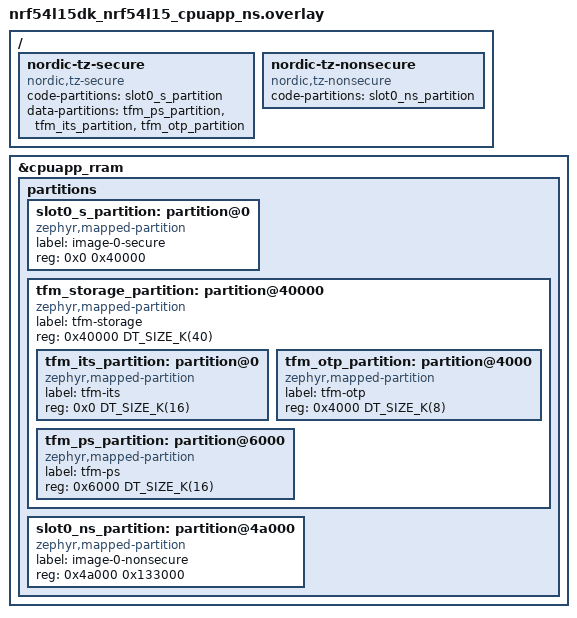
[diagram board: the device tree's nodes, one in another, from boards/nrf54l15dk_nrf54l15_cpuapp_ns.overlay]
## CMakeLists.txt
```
#
# Copyright (c) 2024 Nordic Semiconductor ASA
#
# SPDX-License-Identifier: LicenseRef-Nordic-5-Clause
#

cmake_minimum_required(VERSION 3.13.1)

find_package(Zephyr REQUIRED HINTS $ENV{ZEPHYR_BASE})
project(NONE)

FILE(GLOB app_sources src/*.c)
target_sources(app PRIVATE ${app_sources})
target_include_directories(app PRIVATE src)

add_subdirectory(tests)
```

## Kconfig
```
#
# Copyright (c) 2026 Nordic Semiconductor ASA
#
# SPDX-License-Identifier: LicenseRef-Nordic-5-Clause
#

configdefault HW_UNIQUE_KEY_WRITE_ON_CRYPTO_INIT
	default y

source "Kconfig.zephyr"
```

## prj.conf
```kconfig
#
# Copyright (c) 2021-2024 Nordic Semiconductor ASA
#
# SPDX-License-Identifier: LicenseRef-Nordic-5-Clause
#

CONFIG_ZTEST=y
CONFIG_ZTEST_STACK_SIZE=15360

CONFIG_SYS_CLOCK_TICKS_PER_SEC=1000
CONFIG_MAIN_STACK_SIZE=8192
CONFIG_HEAP_MEM_POOL_SIZE=8192

# Enable logging
CONFIG_CONSOLE=y

# Enable PSA Crypto API
CONFIG_PSA_CRYPTO=y
CONFIG_PSA_CRYPTO_DRIVER_CRACEN=y

CONFIG_HW_UNIQUE_KEY=y
# Ineffective here: unsatisfied dependency (!BUILD_WITH_TFM) on the _ns targets, so
# HW_UNIQUE_KEY_WRITE_ON_CRYPTO_INIT stays n there; moved to Kconfig as a default.
# CONFIG_HW_UNIQUE_KEY_WRITE_ON_CRYPTO_INIT=y

CONFIG_MBEDTLS_ENABLE_HEAP=y
CONFIG_MBEDTLS_HEAP_SIZE=8192

# Enable cryptographic features
CONFIG_PSA_WANT_ECC_TWISTED_EDWARDS_255=y
CONFIG_PSA_WANT_KEY_TYPE_ECC_KEY_PAIR_EXPORT=y

CONFIG_PSA_WANT_ALG_ECDSA=y
CONFIG_PSA_WANT_KEY_TYPE_ECC_KEY_PAIR_IMPORT=y
CONFIG_PSA_WANT_ECC_SECP_R1_256=y
CONFIG_PSA_WANT_ALG_SHA_256=y
CONFIG_PSA_WANT_ALG_SHA_512=y
CONFIG_PSA_WANT_KEY_TYPE_AES=y
CONFIG_PSA_WANT_ALG_CCM=y
CONFIG_PSA_WANT_ALG_CCM_STAR_NO_TAG=y
CONFIG_PSA_WANT_ALG_PURE_EDDSA=y

CONFIG_PSA_WANT_KEY_TYPE_ECC_KEY_PAIR_GENERATE=y
CONFIG_PSA_WANT_GENERATE_RANDOM=y
```

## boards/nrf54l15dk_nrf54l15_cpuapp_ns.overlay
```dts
/*
 * Copyright (c) 2026 Nordic Semiconductor ASA
 *
 * SPDX-License-Identifier: LicenseRef-Nordic-5-Clause
 */

/delete-node/ &slot0_partition;
/delete-node/ &slot0_ns_partition;
/delete-node/ &tfm_ps_partition;
/delete-node/ &tfm_its_partition;
/delete-node/ &tfm_otp_partition;
/delete-node/ &storage_partition;

&cpuapp_rram {
	partitions {
		slot0_s_partition: partition@0 {
			compatible = "zephyr,mapped-partition";
			label = "image-0-secure";
			reg = <0x0 0x40000>;
		};

		tfm_storage_partition: partition@40000 {
			compatible = "zephyr,mapped-partition";
			label = "tfm-storage";
			reg = <0x40000 DT_SIZE_K(40)>;
			ranges = <0x0 0x40000 DT_SIZE_K(40)>;
			#address-cells = <1>;
			#size-cells = <1>;

			tfm_its_partition: partition@0 {
				compatible = "zephyr,mapped-partition";
				label = "tfm-its";
				reg = <0x0 DT_SIZE_K(16)>;
			};

			tfm_otp_partition: partition@4000 {
				compatible = "zephyr,mapped-partition";
				label = "tfm-otp";
				reg = <0x4000 DT_SIZE_K(8)>;
			};

			tfm_ps_partition: partition@6000 {
				compatible = "zephyr,mapped-partition";
				label = "tfm-ps";
				reg = <0x6000 DT_SIZE_K(16)>;
			};
		};

		slot0_ns_partition: partition@4a000 {
			compatible = "zephyr,mapped-partition";
			label = "image-0-nonsecure";
			reg = <0x4a000 0x133000>;
		};
	};
};

/ {
	/delete-node/ nordic-tz-secure;
	/delete-node/ nordic-tz-nonsecure;

	nordic-tz-secure {
		compatible = "nordic,tz-secure";
		code-partitions = <&slot0_s_partition>;
		data-partitions = <&tfm_ps_partition>,
				  <&tfm_its_partition>,
				  <&tfm_otp_partition>;
	};

	nordic-tz-nonsecure {
		compatible = "nordic,tz-nonsecure";
		code-partitions = <&slot0_ns_partition>;
	};
};
```

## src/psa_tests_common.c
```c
/*
 * Copyright (c) 2024 Nordic Semiconductor ASA
 *
 * SPDX-License-Identifier: LicenseRef-Nordic-5-Clause
 */

#include <stdarg.h>
#include <string.h>
#include <stdint.h>
#include <stddef.h>
#include <zephyr/sys/printk.h>

#include <psa/crypto.h>
#include <psa/crypto_values.h>
#include <psa/crypto_extra.h>

#include <zephyr/sys/util.h>
#include <zephyr/sys/clock.h>
#include <zephyr/logging/log.h>
#include <zephyr/ztest.h>
#include "psa_tests_common.h"
#include <hw_unique_key.h>

#ifdef CONFIG_BUILD_WITH_TFM
#include <tfm_ns_interface.h>
#include <tfm_builtin_key_ids.h>
#include "cracen_psa_kmu.h"
#include <tfm_crypto_defs.h>
#else
#include <cracen_psa.h>
#endif

LOG_MODULE_REGISTER(ikg, LOG_LEVEL_INF);

ZTEST_SUITE(test_suite_ikg, NULL, NULL, NULL, NULL, NULL);

static psa_key_id_t key_id;

int crypto_init(void)
{
	psa_status_t status;

#if !defined(CONFIG_BUILD_WITH_TFM)
	if (!hw_unique_key_are_any_written()) {
		status = hw_unique_key_write_random();
		if (status != HW_UNIQUE_KEY_SUCCESS) {
			return status;
		}
	}
#endif
	status = psa_crypto_init();
	if (status != PSA_SUCCESS) {
		return status;
	}
	return APP_SUCCESS;
}

int crypto_finish(void)
{
	psa_status_t status;

	status = psa_destroy_key(key_id);
	if (status != PSA_SUCCESS) {
		return status;
	}

	return APP_SUCCESS;
}
```

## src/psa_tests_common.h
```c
/*
 * Copyright (c) 2024 Nordic Semiconductor ASA
 *
 * SPDX-License-Identifier: LicenseRef-Nordic-5-Clause
 */

#include <stdio.h>
#include <stdarg.h>
#include <stdint.h>
#include <zephyr/toolchain.h>
#include <zephyr/sys/util.h>
#include <zephyr/drivers/entropy.h>

#if defined(CONFIG_ZTEST)
#include <zephyr/ztest.h>
#endif

#define APP_SUCCESS		(0)
#define APP_ERROR		(-1)
#define APP_SUCCESS_MESSAGE "Example finished successfully!"
#define APP_ERROR_MESSAGE "Example exited with error!"

#ifndef TEST_MEMCMP
#define TEST_MEMCMP(x, y, size) ((memcmp(x, y, size) == 0) ? 0 : 1)
#endif

/**@brief Macro asserting equality.
 */
#ifndef TEST_VECTOR_ASSERT_EQUAL
#define TEST_VECTOR_ASSERT_EQUAL(expected, actual)                             \
	zassert_equal((expected), (actual),                                    \
			  "\tAssert values: 0x%04X != -0x%04X", (expected),        \
			  (-actual))
#endif

/**@brief Macro asserting inequality.
 */
#ifndef TEST_VECTOR_ASSERT_NOT_EQUAL
#define TEST_VECTOR_ASSERT_NOT_EQUAL(expected, actual)                         \
	zassert_not_equal((expected), (actual),                                \
			  "\tAssert values: 0x%04X == -0x%04X", (expected),    \
			  (-actual))
#endif

int crypto_finish(void);
int crypto_init(void);
```
